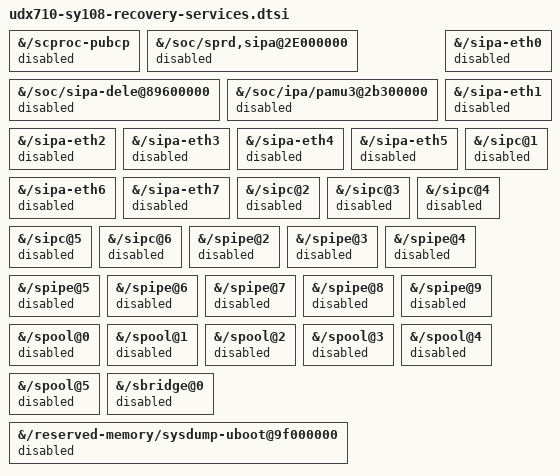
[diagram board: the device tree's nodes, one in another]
// SPDX-License-Identifier: GPL-2.0-only
/* Independent RAM Recovery has no cellular data, NV, CP/DSP loader or CP log
 * consumer. PM_SYS is a platform dependency: preserve SIPC dst6, its mailbox,
 * PM control/log pipes, UART proxy/MCU, DDR, USB, NAND and all reserved memory.
 * Other PCIe/MBIM/USB-offload frontends are already disabled by the base profile.
 */
&{/scproc-pubcp} { status = "disabled"; };
&{/soc/sprd,sipa@2E000000} { status = "disabled"; };
&{/soc/sipa-dele@89600000} { status = "disabled"; };
&{/soc/ipa/pamu3@2b300000} { status = "disabled"; };
&{/sipa-eth0} { status = "disabled"; };
&{/sipa-eth1} { status = "disabled"; };
&{/sipa-eth2} { status = "disabled"; };
&{/sipa-eth3} { status = "disabled"; };
&{/sipa-eth4} { status = "disabled"; };
&{/sipa-eth5} { status = "disabled"; };
&{/sipa-eth6} { status = "disabled"; };
&{/sipa-eth7} { status = "disabled"; };
&{/sipc@1} { status = "disabled"; };
&{/sipc@2} { status = "disabled"; };
&{/sipc@3} { status = "disabled"; };
&{/sipc@4} { status = "disabled"; };
&{/sipc@5} { status = "disabled"; };
&{/sipc@6} { status = "disabled"; };
&{/spipe@2} { status = "disabled"; };
&{/spipe@3} { status = "disabled"; };
&{/spipe@4} { status = "disabled"; };
&{/spipe@5} { status = "disabled"; };
&{/spipe@6} { status = "disabled"; };
&{/spipe@7} { status = "disabled"; };
&{/spipe@8} { status = "disabled"; };
&{/spipe@9} { status = "disabled"; };
&{/spool@0} { status = "disabled"; };
&{/spool@1} { status = "disabled"; };
&{/spool@2} { status = "disabled"; };
&{/spool@3} { status = "disabled"; };
&{/spool@4} { status = "disabled"; };
&{/spool@5} { status = "disabled"; };
&{/sbridge@0} { status = "disabled"; };
/* The old U-Boot fixup reduces this optional dump reservation to size zero.
 * Recovery uses the separate CRC-checked kernel log, not U-Boot RAM dumping.
 */
&{/reserved-memory/sysdump-uboot@9f000000} { status = "disabled"; };
